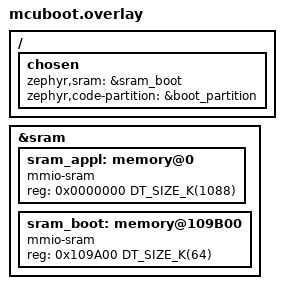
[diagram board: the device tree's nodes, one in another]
/* Overlay to apply to MCUboot domain */

&sram {
	#address-cells = <1>;
	#size-cells = <1>;

	/* RW6XX SRAM can be access by either code or data bus, determined
	 * by the address used to access the memory.
	 * Applications can override the reg properties of either
	 * sram_data or sram_code nodes to change the balance of SRAM access partitioning.
	 */

	sram_appl: memory@0 {
		compatible = "mmio-sram";
		reg = <0x0000000 DT_SIZE_K(1088)>;
	};

	sram_boot: memory@109B00 {
		compatible = "mmio-sram";
		reg = <0x109A00 DT_SIZE_K(64)>;
	};
};

/ {
	chosen {
        zephyr,sram=&sram_boot;
		/* With Sysbuild, enforce MCUboot code in boot_partition */
		zephyr,code-partition = &boot_partition;
	};
};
